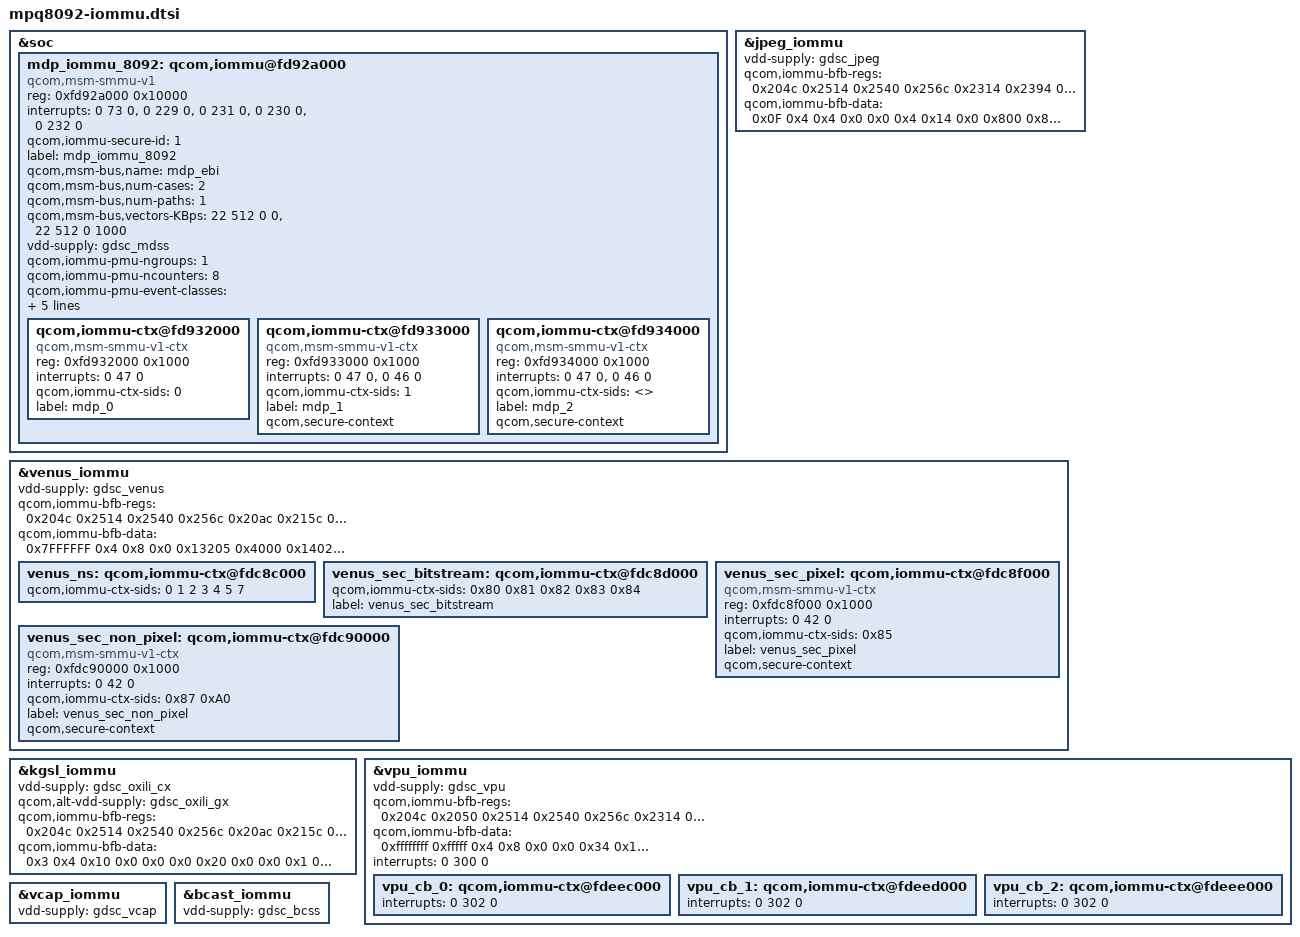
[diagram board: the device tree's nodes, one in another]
/* Copyright (c) 2012-2013, The Linux Foundation. All rights reserved.
 *
 * This program is free software; you can redistribute it and/or modify
 * it under the terms of the GNU General Public License version 2 and
 * only version 2 as published by the Free Software Foundation.
 *
 * This program is distributed in the hope that it will be useful,
 * but WITHOUT ANY WARRANTY; without even the implied warranty of
 * MERCHANTABILITY or FITNESS FOR A PARTICULAR PURPOSE.  See the
 * GNU General Public License for more details.
 */

/include/ "msm-iommu-v1.dtsi"

&soc {
	mdp_iommu_8092: qcom,iommu@fd92a000 {
		compatible = "qcom,msm-smmu-v1";
		#address-cells = <1>;
		#size-cells = <1>;
		ranges;
		reg = <0xfd92a000 0x10000>;
		reg-names = "iommu_base";
		interrupts = <0 73 0>,
				<0 229 0>, <0 231 0>,
				<0 230 0>, <0 232 0>;
		interrupt-names = "pmon",
				"global_cfg_NS_irq", "global_client_NS_irq",
				"global_cfg_S_irq", "global_client_S_irq";
		qcom,iommu-secure-id = <1>;
		label = "mdp_iommu_8092";
		qcom,msm-bus,name = "mdp_ebi";
		qcom,msm-bus,num-cases = <2>;
		qcom,msm-bus,num-paths = <1>;
		qcom,msm-bus,vectors-KBps =
				<22 512 0 0>,
				<22 512 0 1000>;
		status = "ok";
		vdd-supply = <&gdsc_mdss>;

		qcom,iommu-pmu-ngroups = <1>;
		qcom,iommu-pmu-ncounters = <8>;
		qcom,iommu-pmu-event-classes = <0x00
						0x01
						0x08
						0x09
						0x0A
						0x10
						0x11
						0x12
						0x80
						0x81
						0x82
						0x83
						0x90
						0x91
						0x92
						0xb0
						0xb1>;

		qcom,iommu-bfb-regs =  <0x204c
					0x2514
					0x2540
					0x256c
					0x20ac
					0x215c
					0x220c
					0x22bc
					0x2314
					0x2394
					0x2414
					0x2494
					0x2008
					0x200c
					0x2010
					0x2014>;

		qcom,iommu-bfb-data =  <0x3FFFF
					0x4
					0x4
					0x0
					0x1000
					0x0e00
					0x8207
					0x0
					0x0
					0x8
					0x24
					0x0
					0x0
					0x0
					0x0
					0x0>;

		qcom,iommu-ctx@fd932000 {
			compatible = "qcom,msm-smmu-v1-ctx";
			reg = <0xfd932000 0x1000>;
			interrupts = <0 47 0>;
			qcom,iommu-ctx-sids = <0>;
			label = "mdp_0";
		};

		qcom,iommu-ctx@fd933000 {
			compatible = "qcom,msm-smmu-v1-ctx";
			reg = <0xfd933000 0x1000>;
			interrupts = <0 47 0>, <0 46 0>;
			qcom,iommu-ctx-sids = <1>;
			label = "mdp_1";
			qcom,secure-context;
		};

		qcom,iommu-ctx@fd934000 {
			compatible = "qcom,msm-smmu-v1-ctx";
			reg = <0xfd934000 0x1000>;
			interrupts = <0 47 0>, <0 46 0>;
			qcom,iommu-ctx-sids = <>;
			label = "mdp_2";
			qcom,secure-context;
		};
	};
};

&jpeg_iommu {
	status = "ok";
	vdd-supply = <&gdsc_jpeg>;

	qcom,iommu-bfb-regs =  <0x204c
				0x2514
				0x2540
				0x256c
				0x2314
				0x2394
				0x2414
				0x2494
				0x20ac
				0x215c
				0x220c
				0x22bc
				0x2008>;

	qcom,iommu-bfb-data =  <0x0F
				0x4
				0x4
				0x0
				0x0
				0x4
				0x14
				0x0
				0x800
				0x800
				0x3a04
				0x0
				0x0>;
};

&venus_iommu {
	status = "ok";
	vdd-supply = <&gdsc_venus>;

	qcom,iommu-bfb-regs =  <0x204c
				0x2514
				0x2540
				0x256c
				0x20ac
				0x215c
				0x220c
				0x22bc
				0x2314
				0x2394
				0x2414
				0x2494
				0x2008
				0x200c
				0x2010
				0x2014
				0x2018
				0x201c>;

	qcom,iommu-bfb-data =  <0x7FFFFFF
				0x4
				0x8
				0x0
				0x13205
				0x4000
				0x14020
				0x0
				0x0
				0x94
				0x114
				0x0
				0x0
				0x0
				0x0
				0x0
				0x0
				0x0>;

	venus_ns: qcom,iommu-ctx@fdc8c000 {
		qcom,iommu-ctx-sids = <0 1 2 3 4 5 7>;
	};

	venus_sec_bitstream: qcom,iommu-ctx@fdc8d000 {
		qcom,iommu-ctx-sids = <0x80 0x81 0x82 0x83 0x84>;
		label = "venus_sec_bitstream";
	};

	venus_sec_pixel: qcom,iommu-ctx@fdc8f000 {
		compatible = "qcom,msm-smmu-v1-ctx";
		reg = <0xfdc8f000 0x1000>;
		interrupts = <0 42 0>;
		qcom,iommu-ctx-sids = <0x85>;
		label = "venus_sec_pixel";
		qcom,secure-context;
	};

	venus_sec_non_pixel: qcom,iommu-ctx@fdc90000 {
		compatible = "qcom,msm-smmu-v1-ctx";
		reg = <0xfdc90000 0x1000>;
		interrupts = <0 42 0>;
		qcom,iommu-ctx-sids = <0x87 0xA0>;
		label = "venus_sec_non_pixel";
		qcom,secure-context;
	};
};

&kgsl_iommu {
	status = "ok";
	vdd-supply = <&gdsc_oxili_cx>;
	qcom,alt-vdd-supply = <&gdsc_oxili_gx>;

	qcom,iommu-bfb-regs =  <0x204c
				0x2514
				0x2540
				0x256c
				0x20ac
				0x215c
				0x220c
				0x22bc
				0x2314
				0x2394
				0x2414
				0x2494
				0x2008
				0x2600
				0x2604
				0x2608
				0x260c
				0x2610
				0x2614
				0x2618
				0x261c
				0x2620
				0x2624
				0x2628
				0x262c
				0x2630
				0x2634
				0x2638>;

	qcom,iommu-bfb-data =  <0x3
				0x4
				0x10
				0x0
				0x0
				0x0
				0x20
				0x0
				0x0
				0x1
				0x81
				0x0
				0x0
				0x1f
				0x4
				0x8
				0x14
				0x0
				0x0
				0xc
				0x3c
				0x0
				0x4
				0x10
				0x0
				0x15
				0x3020100
				0x04>;
};

&vpu_iommu {
	status = "ok";
	vdd-supply = <&gdsc_vpu>;

	qcom,iommu-bfb-regs =  <0x204c
				0x2050
				0x2514
				0x2540
				0x256c
				0x2314
				0x2394
				0x2414
				0x2494
				0x20ac
				0x215c
				0x220c
				0x22bc
				0x2008
				0x200c
				0x2010
				0x2014
				0x2018
				0x201c
				0x2020
				0x2024
				0x2028
				0x202c
				0x2030>;

	qcom,iommu-bfb-data =  <0xffffffff
				0xfffff
				0x4
				0x8
				0x0
				0x0
				0x34
				0x104
				0x0
				0x6800
				0x6800
				0x18034
				0x0
				0x0
				0x0
				0x0
				0x0
				0x0
				0x0
				0x0
				0x0
				0x0
				0x0
				0x0>;

	interrupts = <0 300 0>;
	vpu_cb_0: qcom,iommu-ctx@fdeec000 {
		interrupts = <0 302 0>;
	};

	vpu_cb_1: qcom,iommu-ctx@fdeed000 {
		interrupts = <0 302 0>;
	};

	vpu_cb_2: qcom,iommu-ctx@fdeee000 {
		interrupts = <0 302 0>;
	};
};

&vcap_iommu {
	status = "ok";
	vdd-supply = <&gdsc_vcap>;
};

&bcast_iommu {
	status = "ok";
	vdd-supply = <&gdsc_bcss>;
};
